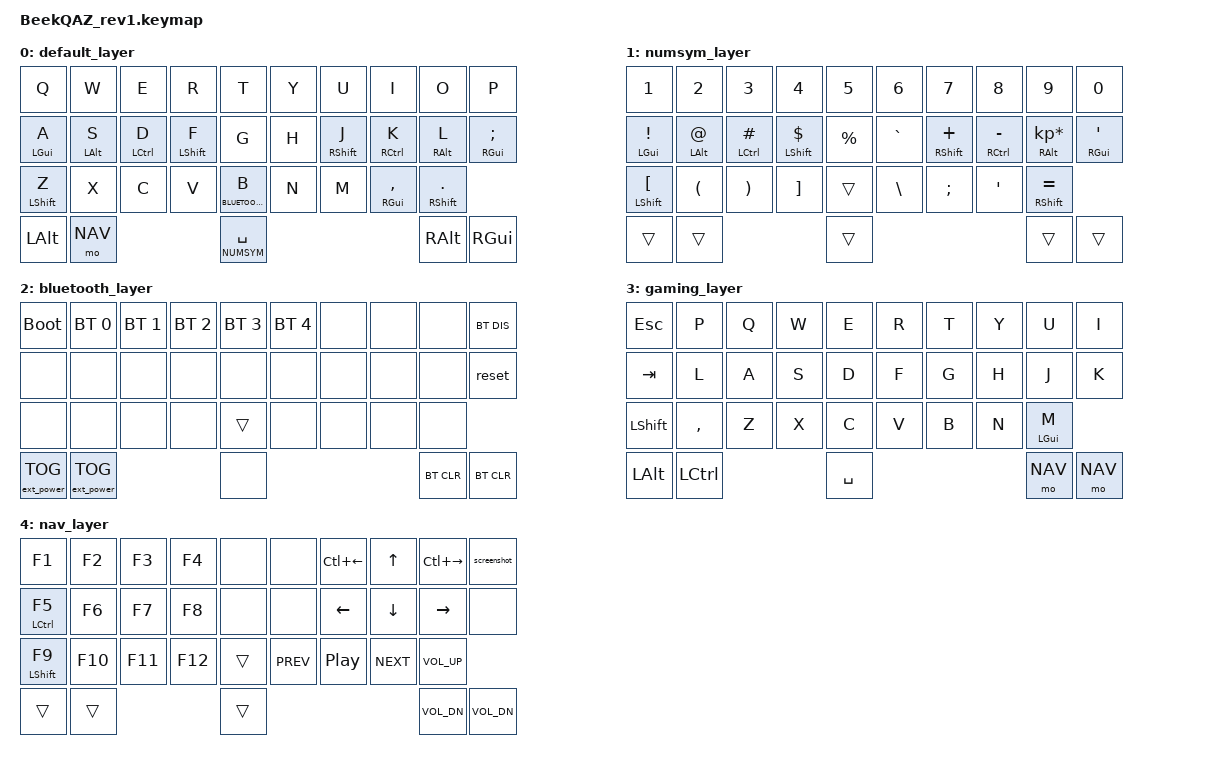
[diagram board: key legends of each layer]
#include <behaviors.dtsi>
#include <dt-bindings/zmk/keys.h>
#include <dt-bindings/zmk/bt.h>
#include <dt-bindings/zmk/outputs.h>
#include <dt-bindings/zmk/rgb.h>
#include <dt-bindings/zmk/ext_power.h>

#define DEFAULT 	0
#define NUMSYM 		1
#define BLUETOOTH	2
#define GAMING 	 	3
#define NAV			4	

#define screenshot LS(LG(S))


/ {
	combos {
	compatible = "zmk,combos";
		combo_esc {
			timeout-ms = <27>;
			key-positions = <0 1>;
			bindings = <&kp ESC>;
		};
		combo_tab {
			timeout-ms = <27>;
			key-positions = <1 2>;
			bindings = <&kp TAB>;
		};
		combo_bpc {
			timeout-ms = <27>;
			key-positions = <17 18>;
			bindings = <&kp BSPC>;
		};
		combo_del {
			timeout-ms = <27>;
			key-positions = <7 8>;
			bindings = <&kp DELETE>;
		};
		combo_ent {
			timeout-ms = <27>;
			key-positions = <18 19>;
			bindings = <&kp ENTER>;
		};
		combo_ask {
			timeout-ms = <27>;
			key-positions = <27 28>;
			bindings = <&kp SLASH>;
		};
		combo_gme {
			timeout-ms = <30>;
			key-positions = <0 9 11 18>;
			bindings = <&tog GAMING>;
		};
		combo_ae {
            timeout-ms = <27>;
            key-positions = <10 11>;
            bindings = <&kp RA(Q) >;
        };
        combo_ue {
            timeout-ms = <27>;
            key-positions = <6 7>;
            bindings = <&kp RA(Y) >;
        };
        combo_oe {
            timeout-ms = <27>;
            key-positions = <8 9>;
            bindings = <&kp RA(P) >;
        };
        combo_ss {
            timeout-ms = <27>;
            key-positions = <11 12>;
            bindings = <&kp RA(S) >;
        };
    };
};

/ {
        behaviors {
        am: alpha_mods {
            compatible = "zmk,behavior-hold-tap";
            label = "ALPHA_MODS";
            #binding-cells = <2>;
            tapping_term_ms = <170>;
            flavor = "tap-preferred";
            bindings = <&kp>, <&kp>;
        };
    };

/*
	Default
	.------------------------------------------------------------.
	|  Q  |  W  |  E  |  R  |  T  |  Y  |  U  |  I  |  O  |   P  |
	|   A  |  S  |  D  |  F  |  G  |  H  |  J  |  K  |  L  |  ;  |
	|    Z    |  X  |  C  |  V  |  B  |  N  |  M  |  ,  |    .   |
	'-----\ SYM |                 SPC                | ALT /-----'
	       '----------------------------------------------'

	Numbers / Symbols
	.------------------------------------------------------------.
	|  1  |  2  |  3  |  4  |  5  |  6  |  7  |  8  |  9  |   0  |
	|   !  |  @  |  #  |  $  |  %  |  `  |  +  |  -  |  *  |  '  |
	|    [    |  (  |  )  |  ]  |     |  \  |  ;  |  '  |    =   |
	'-----\ SYM |                 SPC                | ALT /-----'
	       '----------------------------------------------'
	
	Navigation
	.------------------------------------------------------------.
	| F1  | F2  | F3  | F4  |     |     | ← ← |  ↑  | → → |  ScS |
	|  F5  | F6  | F7  | F8  |     |     |  ←  |  ↓  |  →  |     |
	|   F9    | F10 | F11 | F12 |     | MPR | MPP | MNX |   MVU  |
	'-----\ SYM |                 SPC                | MVD /-----'
	       '----------------------------------------------'

	Gaming
	.------------------------------------------------------------.
	| ESC |  P  |  Q  |  W  |  E  |  R  |  T  |  Y  |  U  |   I  |
	|  TAB |  L  |  A  |  S  |  D  |  F  |  G  |  H  |  J  |  K  |
	|    SFT  |  ,  |  Z  |  X  |  C  |  V  |  B  |  N  | M-WIN  |
	'-----\ CTL |                 SPC                | NAV /-----'
	       '----------------------------------------------'

	Bluetooth
	.------------------------------------------------------------.
	| BL  | BT0 | BT1 | BT3 | BT4 |     |     |     |     |  DIS |
	|      |     |     |     |     |     |     |     |     | RST |
	|         |     |     |     |     |     |     |     |        |
	'-----\ PWR |                                    | CLR /-----'
	       '----------------------------------------------'
*/
	keymap {
		compatible = "zmk,keymap";
		
		default_layer {
			bindings = <
	&kp Q            &kp W         &kp E         &kp R         &kp T            &kp Y            &kp U            &kp I            &kp O            &kp P
    &am LGUI A       &am LALT S    &am LCTRL D   &am LSHFT F   &kp G            &kp H            &am RSHFT J      &am RCTRL K      &am RALT L       &am RGUI SEMI
	&am LSHFT Z      &kp X         &kp C         &kp V         &lt BLUETOOTH B  &kp N            &kp M            &am RGUI CMMA         &am RSHFT DOT         
    &kp LALT         &mo NAV                                   &lt NUMSYM SPACE                                                    &kp RALT         &kp RGUI  
			>;
		};
		numsym_layer {
			bindings = <
	&kp N1           &kp N2        &kp N3        &kp N4        &kp N5           &kp N6           &kp N7           &kp N8           &kp N9           &kp N0   
	&am LGUI EXCL    &am LALT AT   &am LCTRL HASH &am LSHFT DLLR &kp PERCENT    &kp GRAVE        &am RSHFT PLUS   &am RCTRL MINUS  &am RALT KP_ASTERISK &am RGUI SQT
	&am LSHFT LBKT   &kp LPAR      &kp RPAR      &kp RBKT      &trans           &kp BACKSLASH    &kp SEMICOLON    &kp SQT          &am RSHFT EQUAL         
    &trans           &trans                                    &trans                                                              &trans           &trans   
			>;
		};
		bluetooth_layer {
			bindings = <
	&bootloader      &bt BT_SEL 0  &bt BT_SEL 1  &bt BT_SEL 2  &bt BT_SEL 3     &bt BT_SEL 4     &none           &none             &none            &bt BT_DIS
	&none            &none         &none         &none         &none            &none            &none           &none             &none            &reset
	&none            &none         &none         &none         &trans           &none            &none           &none             &none        
    &ext_power EP_TOG&ext_power EP_TOG                         &none                                                               &bt BT_CLR       &bt BT_CLR   
			>;
		};
		gaming_layer {
			bindings = <
	&kp ESC          &kp P         &kp Q         &kp W         &kp E            &kp R            &kp T            &kp Y            &kp U            &kp I
    &kp TAB          &kp L         &kp A         &kp S         &kp D            &kp F            &kp G            &kp H            &kp J            &kp K
	&kp LSHFT        &kp COMMA     &kp Z         &kp X         &kp C            &kp V            &kp B            &kp N            &am LGUI M        
    &kp LALT         &kp LCTRL                                 &kp SPACE                                                           &mo NAV           &mo NAV
			>;
		};
		nav_layer {
			bindings = <
	&kp F1           &kp F2        &kp F3        &kp F4        &none            &none            &kp LC(LEFT)     &kp UP           &kp LC(RIGHT)    &kp screenshot   
	&am LCTRL F5     &kp F6        &kp F7        &kp F8        &none            &none            &kp LEFT         &kp DOWN         &kp RIGHT        &none
	&am LSHFT F9     &kp F10       &kp F11       &kp F12       &trans           &kp C_PREV       &kp C_PP         &kp C_NEXT       &kp C_VOL_UP         
    &trans           &trans                                    &trans                                                              &kp C_VOL_DN     &kp C_VOL_DN   
			>;
		};
	};
};
